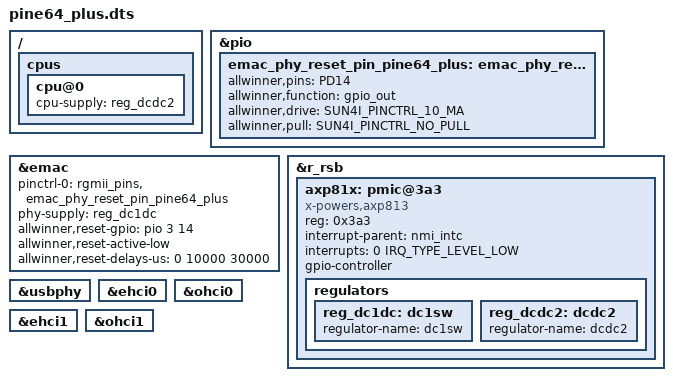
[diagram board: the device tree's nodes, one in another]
/*-
 * Copyright (c) 2016 Jared McNeill <jmcneill@invisible.ca>
 * All rights reserved.
 *
 * Redistribution and use in source and binary forms, with or without
 * modification, are permitted provided that the following conditions
 * are met:
 * 1. Redistributions of source code must retain the above copyright
 *    notice, this list of conditions and the following disclaimer.
 * 2. Redistributions in binary form must reproduce the above copyright
 *    notice, this list of conditions and the following disclaimer in the
 *    documentation and/or other materials provided with the distribution.
 *
 * THIS SOFTWARE IS PROVIDED BY THE AUTHOR AND CONTRIBUTORS ``AS IS'' AND
 * ANY EXPRESS OR IMPLIED WARRANTIES, INCLUDING, BUT NOT LIMITED TO, THE
 * IMPLIED WARRANTIES OF MERCHANTABILITY AND FITNESS FOR A PARTICULAR PURPOSE
 * ARE DISCLAIMED.  IN NO EVENT SHALL THE AUTHOR OR CONTRIBUTORS BE LIABLE
 * FOR ANY DIRECT, INDIRECT, INCIDENTAL, SPECIAL, EXEMPLARY, OR CONSEQUENTIAL
 * DAMAGES (INCLUDING, BUT NOT LIMITED TO, PROCUREMENT OF SUBSTITUTE GOODS
 * OR SERVICES; LOSS OF USE, DATA, OR PROFITS; OR BUSINESS INTERRUPTION)
 * HOWEVER CAUSED AND ON ANY THEORY OF LIABILITY, WHETHER IN CONTRACT, STRICT
 * LIABILITY, OR TORT (INCLUDING NEGLIGENCE OR OTHERWISE) ARISING IN ANY WAY
 * OUT OF THE USE OF THIS SOFTWARE, EVEN IF ADVISED OF THE POSSIBILITY OF
 * SUCH DAMAGE.
 *
 * $FreeBSD$
 */

#include "sun50i-a64-pine64-plus.dts"
#include "a64.dtsi"

#include <dt-bindings/gpio/gpio.h>

/ {
	cpus {
		cpu@0 {
			cpu-supply = <&reg_dcdc2>;
		};
	};
};

&pio {
	emac_phy_reset_pin_pine64_plus: emac_phy_reset_pin@0 {
		allwinner,pins = "PD14";
		allwinner,function = "gpio_out";
		allwinner,drive = <SUN4I_PINCTRL_10_MA>;
		allwinner,pull = <SUN4I_PINCTRL_NO_PULL>;
	};
};

&emac {
	pinctrl-names = "default";
	pinctrl-0 = <&rgmii_pins>, <&emac_phy_reset_pin_pine64_plus>;
	phy-supply = <&reg_dc1dc>;
	allwinner,reset-gpio = <&pio 3 14 GPIO_ACTIVE_HIGH>;
	allwinner,reset-active-low;
	allwinner,reset-delays-us = <0 10000 30000>;
};

&r_rsb {
	status = "okay";

	axp81x: pmic@3a3 {
		compatible = "x-powers,axp813";
		reg = <0x3a3>;
		interrupt-parent = <&nmi_intc>;
		interrupts = <0 IRQ_TYPE_LEVEL_LOW>;
		gpio-controller;
		#gpio-cells = <1>;

		regulators {
			reg_dc1dc: dc1sw {
				regulator-name = "dc1sw";
			};

			reg_dcdc2: dcdc2 {
				regulator-name = "dcdc2";
			};
		};
	};
};

&usbphy {
	status = "okay";
};

&ehci0 {
	status = "okay";
};

&ohci0 {
	status = "okay";
};

&ehci1 {
	status = "okay";
};

&ohci1 {
	status = "okay";
};
